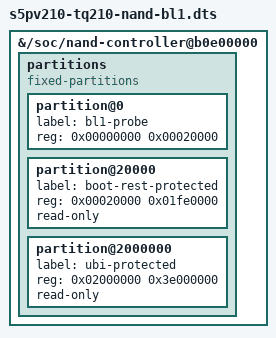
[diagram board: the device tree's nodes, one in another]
// SPDX-License-Identifier: GPL-2.0
#include "s5pv210-tq210-nand-bch.dts"

/* Explicit RAM rescue BL1 probe only; never mount UBI here. */
&{/soc/nand-controller@b0e00000} {
	partitions {
		compatible = "fixed-partitions";
		#address-cells = <1>;
		#size-cells = <1>;
		partition@0 {
			label = "bl1-probe";
			reg = <0x00000000 0x00020000>;
		};
		partition@20000 {
			label = "boot-rest-protected";
			reg = <0x00020000 0x01fe0000>;
			read-only;
		};
		partition@2000000 {
			label = "ubi-protected";
			reg = <0x02000000 0x3e000000>;
			read-only;
		};
	};
};
